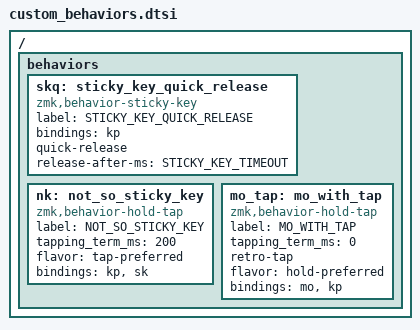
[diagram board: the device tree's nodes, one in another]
/ {

  behaviors {
    skq: sticky_key_quick_release {
      compatible = "zmk,behavior-sticky-key";
      label = "STICKY_KEY_QUICK_RELEASE";
      #binding-cells = <1>;
      bindings = <&kp>;
      quick-release;
      release-after-ms = <STICKY_KEY_TIMEOUT>;
    };

    // Sticky key on tap, normal key on hold
    // Useful for modifier-clicking without the modifier remaining active
    nk: not_so_sticky_key {
      compatible = "zmk,behavior-hold-tap";
      label = "NOT_SO_STICKY_KEY";
      #binding-cells = <2>;
      tapping_term_ms = <200>;
      flavor = "tap-preferred";
      bindings = <&kp>, <&sk>;
    };

    // A hold-tap that activates without delay (like `&mo`)
    mo_tap: mo_with_tap {
      compatible = "zmk,behavior-hold-tap";
      label = "MO_WITH_TAP";
      #binding-cells = <2>;
      tapping_term_ms = <0>;
      retro-tap;
      flavor = "hold-preferred";
      bindings = <&mo>, <&kp>;
    };
  };
};
